# S32K118_M0P register map
Vendor: NXP Semiconductors; File version: 1.1
CPU: CM0PLUS r0p0, little endian, MPU, FPU, VTOR, 4 interrupt priority bits
Registers are 32-bit, read-write, reset 0x0 unless marked. A register's access mark holds for its fields unless they carry their own. Offsets are from the block's base; [hi:lo] are bit positions; {n}, {i} and the like mark numbered series; 'fields as' and 'values as' point back to an identical list.

## DMAMUX
Base 0x40021000
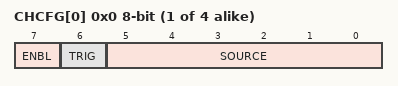
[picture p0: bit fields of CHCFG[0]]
{0x0+i} CHCFG[{i}] (i=0..3) 8-bit — Channel Configuration register
  [7] ENBL — DMA Channel Enable
    0=DMA channel is disabled. This mode is primarily used during configuration of the DMAMux. The DMA has separate channel enables/disables, which should be used to disable or reconfigure a DMA channel.; 1=DMA channel is enabled
  [6] TRIG — DMA Channel Trigger Enable
    0=Triggering is disabled. If triggering is disabled and ENBL is set, the DMA Channel will simply route the specified source to the DMA channel. (Normal mode); 1=Triggering is enabled. If triggering is enabled and ENBL is set, the DMAMUX is in Periodic Trigger mode.
  [5:0] SOURCE — DMA Channel Source (Slot)

## CRC
Base 0x40032000
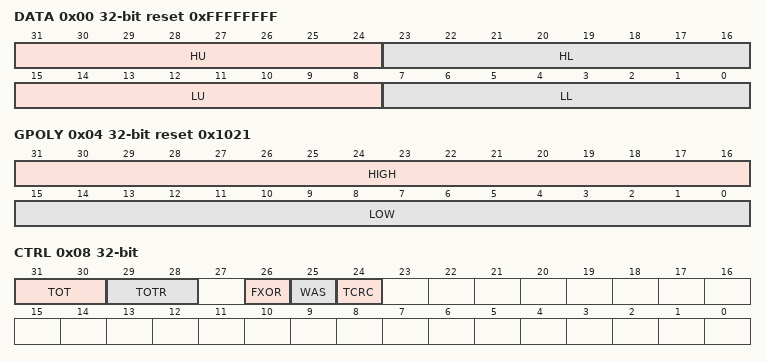
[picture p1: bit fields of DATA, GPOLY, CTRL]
0x00 DATA reset 0xFFFFFFFF — CRC Data register
  [31:24] HU — CRC High Upper Byte
  [23:16] HL — CRC High Lower Byte
  [15:8] LU — CRC Low Upper Byte
  [7:0] LL — CRC Low Lower Byte
0x04 GPOLY reset 0x1021 — CRC Polynomial register
  [31:16] HIGH — High Polynominal Half-word
  [15:0] LOW — Low Polynominal Half-word
0x08 CTRL — CRC Control register
  [31:30] TOT — Type Of Transpose For Writes
    0=No transposition; 1=Bits in bytes are transposed; bytes are not transposed; 2=Both bits in bytes and bytes are transposed; 3=Only bytes are transposed; no bits in a byte are transposed
  [29:28] TOTR — Type Of Transpose For Read
    values as TOT
  [26] FXOR — Complement Read Of CRC Data Register
    0=No XOR on reading; 1=Invert or complement the read value of the CRC Data register
  [25] WAS — Write CRC Data Register As Seed
    0=Writes to the CRC data register are data values; 1=Writes to the CRC data register are seed values
  [24] TCRC
    0=16-bit CRC protocol; 1=32-bit CRC protocol

## CMU0 — CMU_FC
Base 0x4003E000
Same registers: CMU1 0x4003F000
0x00 GCR — Global Configuration Register
  [0] FCE — Frequency Check Enable.
    0=bfv_gcr_fce_0 (Frequency check disabled); 1=bfv_gcr_fce_1 (Frequency check enabled)
0x04 RCCR — Reference Count Configuration Register
  [15:0] REF_CNT — Reference clock count.
0x08 HTCR reset 0xFFFFFF — High Threshold Configuration Register
  [23:0] HFREF — High frequency reference threshold.
0x0C LTCR — Low Threshold Configuration Register
  [23:0] LFREF — Low Frequency Reference Threshold.
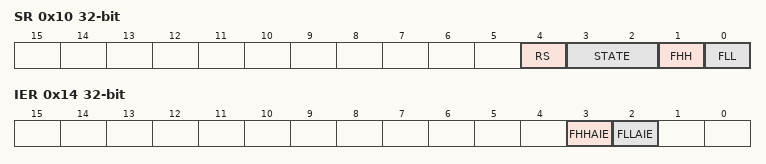
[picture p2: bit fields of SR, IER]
0x10 SR — Status Register
  [4] RS ro — Run Status
    0=bfv_sr_rs_0 (Frequency check stopped); 1=bfv_sr_rs_1 (Frequency check running)
  [3:2] STATE ro — Module state
    0=bfv_sr_state_0 (Configure state: Configuration of registers and IER programming are in progress.); 1=bfv_sr_state_1 (Initialization state: Register configurations are being loaded internally.); 2=bfv_sr_state_2 (Initialization wait state: CMU_FC stays in this state for one bus clock cycle.); 3=bfv_sr_state_3 (Frequency check state: CMU_FC is ready to start frequency check operation in this state.)
  [1] FHH write-1-clears — Frequency higher than high frequency reference threshold event status.
    0=bfv_sr_fhh_0 (No FHH event); 1=bfv_sr_fhh_1 (FHH event occurred)
  [0] FLL write-1-clears — Frequency lower than low frequency reference threshold event status.
    0=bfv_sr_fll_0 (No FLL event); 1=bfv_sr_fll_1 (FLL event captured)
0x14 IER — Interrupt Enable Register
  [3] FHHAIE — Frequency Higher than High Frequency Reference Threshold Asynchronous Interrupt enable
    0=bfv_ier_fhhaie_0 (Asynchronous FHH interrupt disabled); 1=bfv_ier_fhhaie_1 (Asynchronous FHH interrupt enabled)
  [2] FLLAIE — Frequency Lower than Low Frequency Reference Threshold Asynchronous Interrupt Enable
    0=bfv_ier_fllaie_0 (Asynchronous FLL interrupt disabled); 1=bfv_ier_fllaie_1 (Asynchronous FLL interrupt enabled)
